# crc register map
Vendor: Texas Instruments
Peripheral module from a debugger description file (folder MSP432E4).
Registers are 32-bit, read-write, no defined reset value unless marked. A register's access mark holds for its fields unless they carry their own. Offsets are as the file gives them; lines under a group give offsets from that group; [hi:lo] are bit positions; {n}, {i} and the like mark numbered series; 'fields as' and 'values as' point back to an identical list; <NAME> marks a mode.

## CRC — EC register offsets
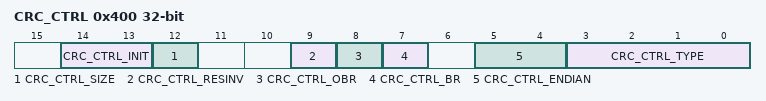
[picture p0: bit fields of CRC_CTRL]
0x400 CRC_CTRL — CRC Control
  [14:13] CRC_CTRL_INIT — CRC Initialization
    0=CRC_CTRL_INIT_SEED (Use the CRC_SEED register context as the starting value); 2=Initialize to all '0s'; 3=Initialize to all '1s'
  [12] CRC_CTRL_SIZE — Input Data Size
  [9] CRC_CTRL_RESINV — Result Inverse Enable
  [8] CRC_CTRL_OBR — Output Reverse Enable
  [7] CRC_CTRL_BR — Bit reverse enable
  [5:4] CRC_CTRL_ENDIAN — Endian Control
    0=CRC_CTRL_ENDIAN_SBHW (Configuration unchanged. (B3, B2, B1, B0)); 1=CRC_CTRL_ENDIAN_SHW (Bytes are swapped in half-words but half-words are not swapped (B2, B3, B0, B1)); 2=CRC_CTRL_ENDIAN_SHWNB (Half-words are swapped but bytes are not swapped in half-word. (B1, B0, B3, B2)); 3=CRC_CTRL_ENDIAN_SBSW (Bytes are swapped in half-words and half-words are swapped. (B0, B1, B2, B3))
  [3:0] CRC_CTRL_TYPE — Operation Type
    0=CRC_CTRL_TYPE_P8055 (Polynomial 0x8005); 1=CRC_CTRL_TYPE_P1021 (Polynomial 0x1021); 2=CRC_CTRL_TYPE_P4C11DB7 (Polynomial 0x4C11DB7); 3=CRC_CTRL_TYPE_P1EDC6F41 (Polynomial 0x1EDC6F41); 8=CRC_CTRL_TYPE_TCPCHKSUM (TCP checksum)
0x410 CRC_SEED — CRC SEED/Context
  [31:0] CRC_SEED_SEED — SEED/Context Value
0x414 CRC_DIN — CRC Data Input
  [31:0] CRC_DIN_DATAIN — Data Input
0x418 CRC_RSLTPP ro — CRC Post Processing Result
  [31:0] CRC_RSLTPP_RSLTPP — Post Processing Result
